# ESP32-H4 register map
Vendor: ESPRESSIF SYSTEMS (SHANGHAI) CO., LTD.; Series: ESP32 H-Series; File version: 1
CPU: RV32IMAC r0p0, little endian, no MPU, no FPU, 0 interrupt priority bits
Address unit: 32 bits
Registers are 32-bit, read-write, reset 0x0 unless marked. A register's access mark holds for its fields unless they carry their own. Offsets are from the block's base; [hi:lo] are bit positions; {n}, {i} and the like mark numbered series.

## INTERRUPT_CORE0 — Interrupt Controller (Core 0)
Base 0x6009A000
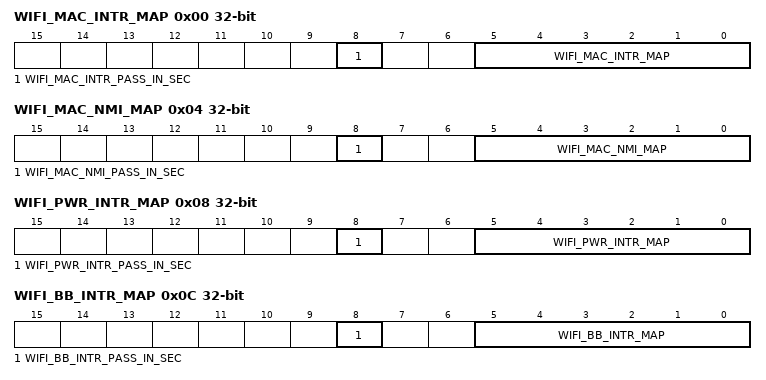
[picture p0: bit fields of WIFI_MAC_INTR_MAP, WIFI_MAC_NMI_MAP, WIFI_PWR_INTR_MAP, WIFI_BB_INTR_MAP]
0x00 WIFI_MAC_INTR_MAP — WIFI_MAC_INTR mapping register
  [8] WIFI_MAC_INTR_PASS_IN_SEC — Configures the PASS_IN_SEC flag of the interrupt source.
  [5:0] WIFI_MAC_INTR_MAP — Configures the interrupt source into one CPU interrupt.
0x04 WIFI_MAC_NMI_MAP — WIFI_MAC_NMI mapping register
  [8] WIFI_MAC_NMI_PASS_IN_SEC — Configures the PASS_IN_SEC flag of the interrupt source.
  [5:0] WIFI_MAC_NMI_MAP — Configures the interrupt source into one CPU interrupt.
0x08 WIFI_PWR_INTR_MAP — WIFI_PWR_INTR mapping register
  [8] WIFI_PWR_INTR_PASS_IN_SEC — Configures the PASS_IN_SEC flag of the interrupt source.
  [5:0] WIFI_PWR_INTR_MAP — Configures the interrupt source into one CPU interrupt.
0x0C WIFI_BB_INTR_MAP — WIFI_BB_INTR mapping register
  [8] WIFI_BB_INTR_PASS_IN_SEC — Configures the PASS_IN_SEC flag of the interrupt source.
  [5:0] WIFI_BB_INTR_MAP — Configures the interrupt source into one CPU interrupt.
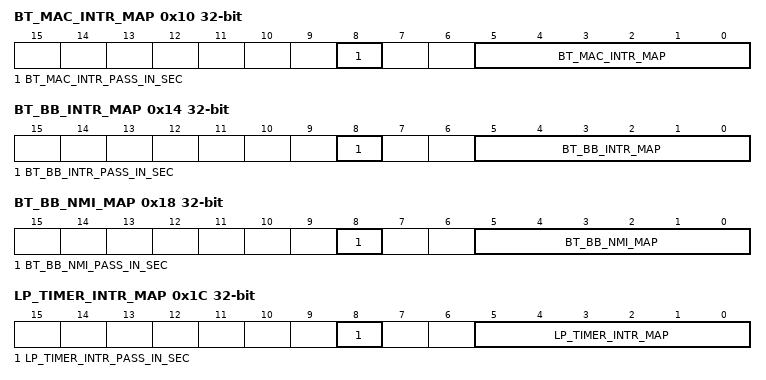
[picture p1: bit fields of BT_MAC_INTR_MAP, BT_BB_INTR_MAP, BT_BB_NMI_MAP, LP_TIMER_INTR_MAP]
0x10 BT_MAC_INTR_MAP — BT_MAC_INTR mapping register
  [8] BT_MAC_INTR_PASS_IN_SEC — Configures the PASS_IN_SEC flag of the interrupt source.
  [5:0] BT_MAC_INTR_MAP — Configures the interrupt source into one CPU interrupt.
0x14 BT_BB_INTR_MAP — BT_BB_INTR mapping register
  [8] BT_BB_INTR_PASS_IN_SEC — Configures the PASS_IN_SEC flag of the interrupt source.
  [5:0] BT_BB_INTR_MAP — Configures the interrupt source into one CPU interrupt.
0x18 BT_BB_NMI_MAP — BT_BB_NMI mapping register
  [8] BT_BB_NMI_PASS_IN_SEC — Configures the PASS_IN_SEC flag of the interrupt source.
  [5:0] BT_BB_NMI_MAP — Configures the interrupt source into one CPU interrupt.
0x1C LP_TIMER_INTR_MAP — LP_TIMER_INTR mapping register
  [8] LP_TIMER_INTR_PASS_IN_SEC — Configures the PASS_IN_SEC flag of the interrupt source.
  [5:0] LP_TIMER_INTR_MAP — Configures the interrupt source into one CPU interrupt.
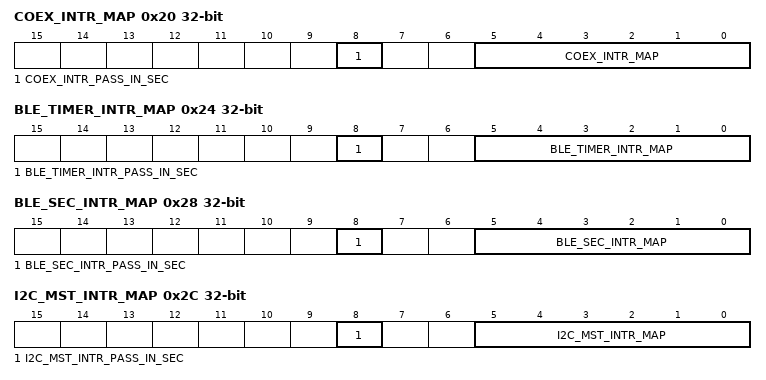
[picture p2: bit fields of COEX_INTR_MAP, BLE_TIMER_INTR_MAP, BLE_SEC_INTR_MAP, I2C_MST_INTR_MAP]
0x20 COEX_INTR_MAP — COEX_INTR mapping register
  [8] COEX_INTR_PASS_IN_SEC — Configures the PASS_IN_SEC flag of the interrupt source.
  [5:0] COEX_INTR_MAP — Configures the interrupt source into one CPU interrupt.
0x24 BLE_TIMER_INTR_MAP — BLE_TIMER_INTR mapping register
  [8] BLE_TIMER_INTR_PASS_IN_SEC — Configures the PASS_IN_SEC flag of the interrupt source.
  [5:0] BLE_TIMER_INTR_MAP — Configures the interrupt source into one CPU interrupt.
0x28 BLE_SEC_INTR_MAP — BLE_SEC_INTR mapping register
  [8] BLE_SEC_INTR_PASS_IN_SEC — Configures the PASS_IN_SEC flag of the interrupt source.
  [5:0] BLE_SEC_INTR_MAP — Configures the interrupt source into one CPU interrupt.
0x2C I2C_MST_INTR_MAP — I2C_MST_INTR mapping register
  [8] I2C_MST_INTR_PASS_IN_SEC — Configures the PASS_IN_SEC flag of the interrupt source.
  [5:0] I2C_MST_INTR_MAP — Configures the interrupt source into one CPU interrupt.
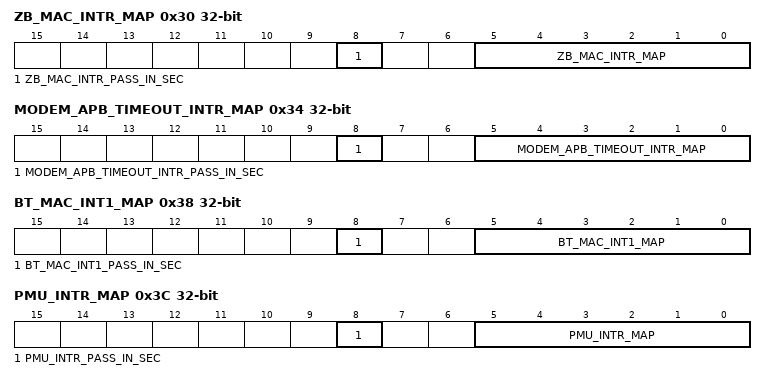
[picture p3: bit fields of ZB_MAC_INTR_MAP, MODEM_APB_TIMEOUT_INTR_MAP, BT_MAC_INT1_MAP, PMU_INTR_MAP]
0x30 ZB_MAC_INTR_MAP — ZB_MAC_INTR mapping register
  [8] ZB_MAC_INTR_PASS_IN_SEC — Configures the PASS_IN_SEC flag of the interrupt source.
  [5:0] ZB_MAC_INTR_MAP — Configures the interrupt source into one CPU interrupt.
0x34 MODEM_APB_TIMEOUT_INTR_MAP — MODEM_APB_TIMEOUT_INTR mapping register
  [8] MODEM_APB_TIMEOUT_INTR_PASS_IN_SEC — Configures the PASS_IN_SEC flag of the interrupt source.
  [5:0] MODEM_APB_TIMEOUT_INTR_MAP — Configures the interrupt source into one CPU interrupt.
0x38 BT_MAC_INT1_MAP — BT_MAC_INT1 mapping register
  [8] BT_MAC_INT1_PASS_IN_SEC — Configures the PASS_IN_SEC flag of the interrupt source.
  [5:0] BT_MAC_INT1_MAP — Configures the interrupt source into one CPU interrupt.
0x3C PMU_INTR_MAP — PMU_INTR mapping register
  [8] PMU_INTR_PASS_IN_SEC — Configures the PASS_IN_SEC flag of the interrupt source.
  [5:0] PMU_INTR_MAP — Configures the interrupt source into one CPU interrupt.
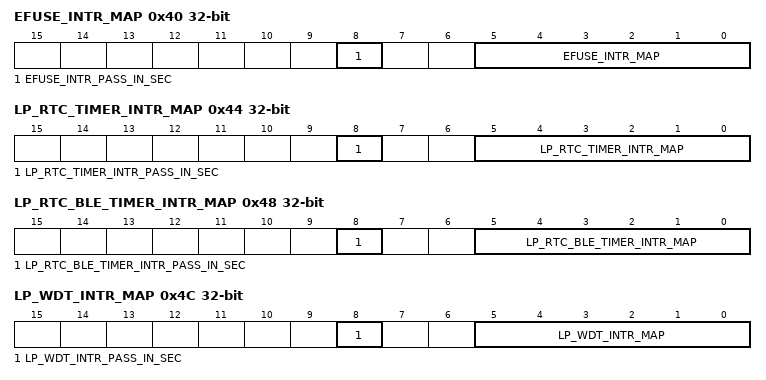
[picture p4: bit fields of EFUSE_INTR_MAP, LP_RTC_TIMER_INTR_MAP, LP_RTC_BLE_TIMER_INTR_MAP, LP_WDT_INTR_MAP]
0x40 EFUSE_INTR_MAP — EFUSE_INTR mapping register
  [8] EFUSE_INTR_PASS_IN_SEC — Configures the PASS_IN_SEC flag of the interrupt source.
  [5:0] EFUSE_INTR_MAP — Configures the interrupt source into one CPU interrupt.
0x44 LP_RTC_TIMER_INTR_MAP — LP_RTC_TIMER_INTR mapping register
  [8] LP_RTC_TIMER_INTR_PASS_IN_SEC — Configures the PASS_IN_SEC flag of the interrupt source.
  [5:0] LP_RTC_TIMER_INTR_MAP — Configures the interrupt source into one CPU interrupt.
0x48 LP_RTC_BLE_TIMER_INTR_MAP — LP_RTC_BLE_TIMER_INTR mapping register
  [8] LP_RTC_BLE_TIMER_INTR_PASS_IN_SEC — Configures the PASS_IN_SEC flag of the interrupt source.
  [5:0] LP_RTC_BLE_TIMER_INTR_MAP — Configures the interrupt source into one CPU interrupt.
0x4C LP_WDT_INTR_MAP — LP_WDT_INTR mapping register
  [8] LP_WDT_INTR_PASS_IN_SEC — Configures the PASS_IN_SEC flag of the interrupt source.
  [5:0] LP_WDT_INTR_MAP — Configures the interrupt source into one CPU interrupt.
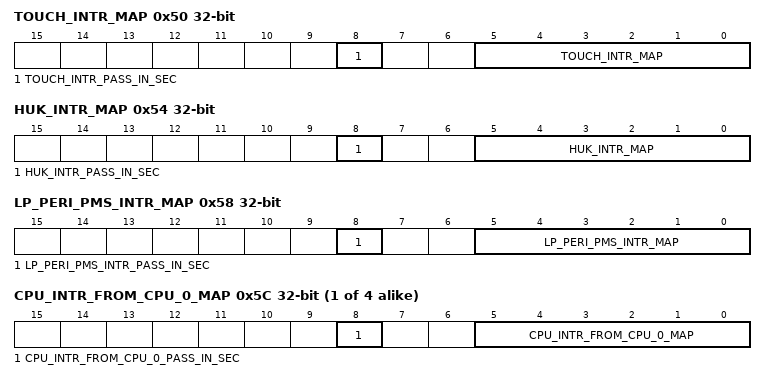
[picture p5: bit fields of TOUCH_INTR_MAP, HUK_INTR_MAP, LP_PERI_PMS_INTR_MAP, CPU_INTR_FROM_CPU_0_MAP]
0x50 TOUCH_INTR_MAP — TOUCH_INTR mapping register
  [8] TOUCH_INTR_PASS_IN_SEC — Configures the PASS_IN_SEC flag of the interrupt source.
  [5:0] TOUCH_INTR_MAP — Configures the interrupt source into one CPU interrupt.
0x54 HUK_INTR_MAP — HUK_INTR mapping register
  [8] HUK_INTR_PASS_IN_SEC — Configures the PASS_IN_SEC flag of the interrupt source.
  [5:0] HUK_INTR_MAP — Configures the interrupt source into one CPU interrupt.
0x58 LP_PERI_PMS_INTR_MAP — LP_PERI_PMS_INTR mapping register
  [8] LP_PERI_PMS_INTR_PASS_IN_SEC — Configures the PASS_IN_SEC flag of the interrupt source.
  [5:0] LP_PERI_PMS_INTR_MAP — Configures the interrupt source into one CPU interrupt.
{0x5C+4i} CPU_INTR_FROM_CPU_{i}_MAP (i=0..3) — CPU_INTR_FROM_CPU_{i} mapping register
  [8] CPU_INTR_FROM_CPU_{i}_PASS_IN_SEC — Configures the PASS_IN_SEC flag of the interrupt source.
  [5:0] CPU_INTR_FROM_CPU_{i}_MAP — Configures the interrupt source into one CPU interrupt.
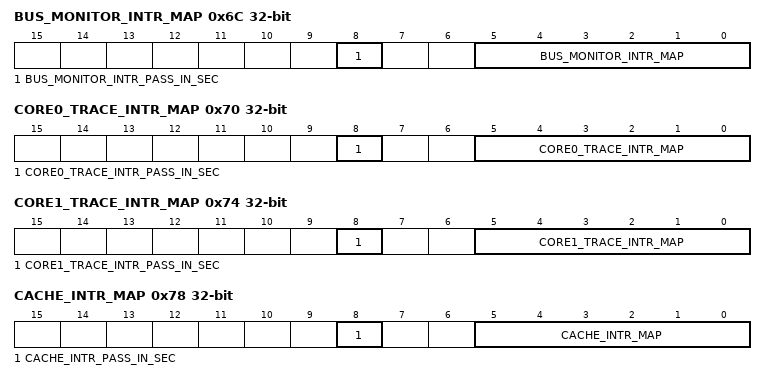
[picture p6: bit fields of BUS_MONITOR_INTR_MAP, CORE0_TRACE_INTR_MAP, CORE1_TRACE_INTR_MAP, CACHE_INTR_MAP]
0x6C BUS_MONITOR_INTR_MAP — BUS_MONITOR_INTR mapping register
  [8] BUS_MONITOR_INTR_PASS_IN_SEC — Configures the PASS_IN_SEC flag of the interrupt source.
  [5:0] BUS_MONITOR_INTR_MAP — Configures the interrupt source into one CPU interrupt.
0x70 CORE0_TRACE_INTR_MAP — CORE0_TRACE_INTR mapping register
  [8] CORE0_TRACE_INTR_PASS_IN_SEC — Configures the PASS_IN_SEC flag of the interrupt source.
  [5:0] CORE0_TRACE_INTR_MAP — Configures the interrupt source into one CPU interrupt.
0x74 CORE1_TRACE_INTR_MAP — CORE1_TRACE_INTR mapping register
  [8] CORE1_TRACE_INTR_PASS_IN_SEC — Configures the PASS_IN_SEC flag of the interrupt source.
  [5:0] CORE1_TRACE_INTR_MAP — Configures the interrupt source into one CPU interrupt.
0x78 CACHE_INTR_MAP — CACHE_INTR mapping register
  [8] CACHE_INTR_PASS_IN_SEC — Configures the PASS_IN_SEC flag of the interrupt source.
  [5:0] CACHE_INTR_MAP — Configures the interrupt source into one CPU interrupt.
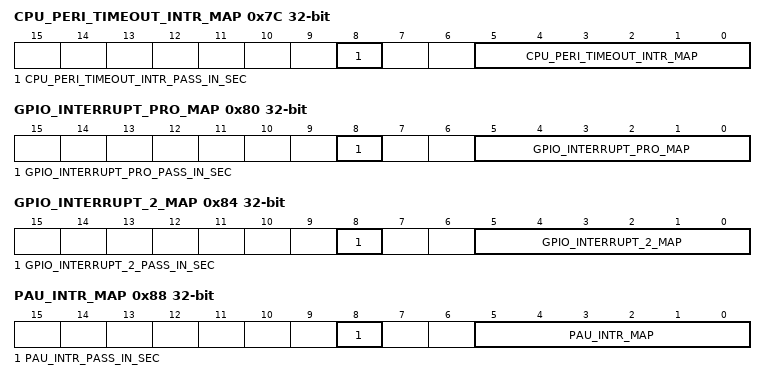
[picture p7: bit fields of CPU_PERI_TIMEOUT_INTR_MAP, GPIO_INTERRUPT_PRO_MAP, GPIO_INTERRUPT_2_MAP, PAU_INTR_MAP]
0x7C CPU_PERI_TIMEOUT_INTR_MAP — CPU_PERI_TIMEOUT_INTR mapping register
  [8] CPU_PERI_TIMEOUT_INTR_PASS_IN_SEC — Configures the PASS_IN_SEC flag of the interrupt source.
  [5:0] CPU_PERI_TIMEOUT_INTR_MAP — Configures the interrupt source into one CPU interrupt.
0x80 GPIO_INTERRUPT_PRO_MAP — GPIO_INTERRUPT_PRO mapping register
  [8] GPIO_INTERRUPT_PRO_PASS_IN_SEC — Configures the PASS_IN_SEC flag of the interrupt source.
  [5:0] GPIO_INTERRUPT_PRO_MAP — Configures the interrupt source into one CPU interrupt.
0x84 GPIO_INTERRUPT_2_MAP — GPIO_INTERRUPT_2 mapping register
  [8] GPIO_INTERRUPT_2_PASS_IN_SEC — Configures the PASS_IN_SEC flag of the interrupt source.
  [5:0] GPIO_INTERRUPT_2_MAP — Configures the interrupt source into one CPU interrupt.
0x88 PAU_INTR_MAP — PAU_INTR mapping register
  [8] PAU_INTR_PASS_IN_SEC — Configures the PASS_IN_SEC flag of the interrupt source.
  [5:0] PAU_INTR_MAP — Configures the interrupt source into one CPU interrupt.
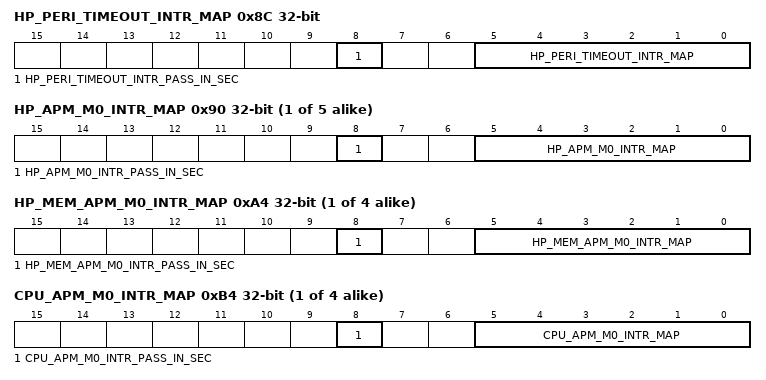
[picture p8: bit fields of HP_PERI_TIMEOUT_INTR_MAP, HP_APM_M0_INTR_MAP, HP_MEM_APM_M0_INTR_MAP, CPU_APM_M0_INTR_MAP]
0x8C HP_PERI_TIMEOUT_INTR_MAP — HP_PERI_TIMEOUT_INTR mapping register
  [8] HP_PERI_TIMEOUT_INTR_PASS_IN_SEC — Configures the PASS_IN_SEC flag of the interrupt source.
  [5:0] HP_PERI_TIMEOUT_INTR_MAP — Configures the interrupt source into one CPU interrupt.
{0x90+4i} HP_APM_M{i}_INTR_MAP (i=0..4) — HP_APM_M{i}_INTR mapping register
  [8] HP_APM_M{i}_INTR_PASS_IN_SEC — Configures the PASS_IN_SEC flag of the interrupt source.
  [5:0] HP_APM_M{i}_INTR_MAP — Configures the interrupt source into one CPU interrupt.
{0xA4+4i} HP_MEM_APM_M{i}_INTR_MAP (i=0..3) — HP_MEM_APM_M{i}_INTR mapping register
  [8] HP_MEM_APM_M{i}_INTR_PASS_IN_SEC — Configures the PASS_IN_SEC flag of the interrupt source.
  [5:0] HP_MEM_APM_M{i}_INTR_MAP — Configures the interrupt source into one CPU interrupt.
{0xB4+4i} CPU_APM_M{i}_INTR_MAP (i=0..3) — CPU_APM_M{i}_INTR mapping register
  [8] CPU_APM_M{i}_INTR_PASS_IN_SEC — Configures the PASS_IN_SEC flag of the interrupt source.
  [5:0] CPU_APM_M{i}_INTR_MAP — Configures the interrupt source into one CPU interrupt.
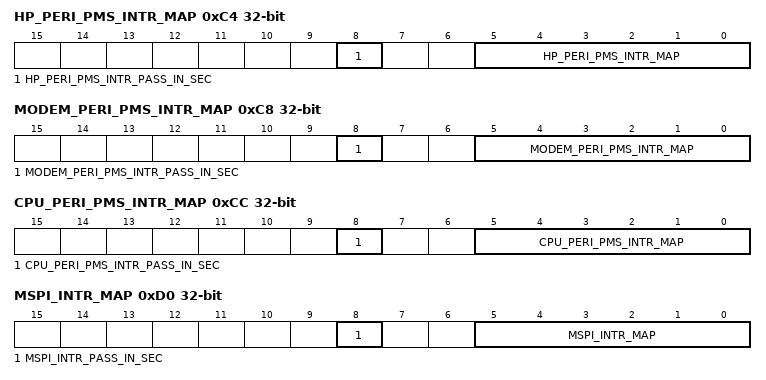
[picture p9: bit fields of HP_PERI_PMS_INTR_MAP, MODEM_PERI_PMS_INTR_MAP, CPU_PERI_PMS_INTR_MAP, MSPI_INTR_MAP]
0xC4 HP_PERI_PMS_INTR_MAP — HP_PERI_PMS_INTR mapping register
  [8] HP_PERI_PMS_INTR_PASS_IN_SEC — Configures the PASS_IN_SEC flag of the interrupt source.
  [5:0] HP_PERI_PMS_INTR_MAP — Configures the interrupt source into one CPU interrupt.
0xC8 MODEM_PERI_PMS_INTR_MAP — MODEM_PERI_PMS_INTR mapping register
  [8] MODEM_PERI_PMS_INTR_PASS_IN_SEC — Configures the PASS_IN_SEC flag of the interrupt source.
  [5:0] MODEM_PERI_PMS_INTR_MAP — Configures the interrupt source into one CPU interrupt.
0xCC CPU_PERI_PMS_INTR_MAP — CPU_PERI_PMS_INTR mapping register
  [8] CPU_PERI_PMS_INTR_PASS_IN_SEC — Configures the PASS_IN_SEC flag of the interrupt source.
  [5:0] CPU_PERI_PMS_INTR_MAP — Configures the interrupt source into one CPU interrupt.
0xD0 MSPI_INTR_MAP — MSPI_INTR mapping register
  [8] MSPI_INTR_PASS_IN_SEC — Configures the PASS_IN_SEC flag of the interrupt source.
  [5:0] MSPI_INTR_MAP — Configures the interrupt source into one CPU interrupt.
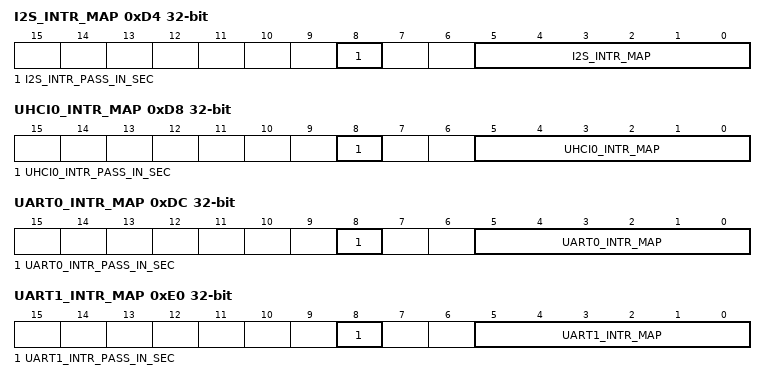
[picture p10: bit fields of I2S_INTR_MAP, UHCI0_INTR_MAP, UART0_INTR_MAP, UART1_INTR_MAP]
0xD4 I2S_INTR_MAP — I2S_INTR mapping register
  [8] I2S_INTR_PASS_IN_SEC — Configures the PASS_IN_SEC flag of the interrupt source.
  [5:0] I2S_INTR_MAP — Configures the interrupt source into one CPU interrupt.
0xD8 UHCI0_INTR_MAP — UHCI0_INTR mapping register
  [8] UHCI0_INTR_PASS_IN_SEC — Configures the PASS_IN_SEC flag of the interrupt source.
  [5:0] UHCI0_INTR_MAP — Configures the interrupt source into one CPU interrupt.
0xDC UART0_INTR_MAP — UART0_INTR mapping register
  [8] UART0_INTR_PASS_IN_SEC — Configures the PASS_IN_SEC flag of the interrupt source.
  [5:0] UART0_INTR_MAP — Configures the interrupt source into one CPU interrupt.
0xE0 UART1_INTR_MAP — UART1_INTR mapping register
  [8] UART1_INTR_PASS_IN_SEC — Configures the PASS_IN_SEC flag of the interrupt source.
  [5:0] UART1_INTR_MAP — Configures the interrupt source into one CPU interrupt.
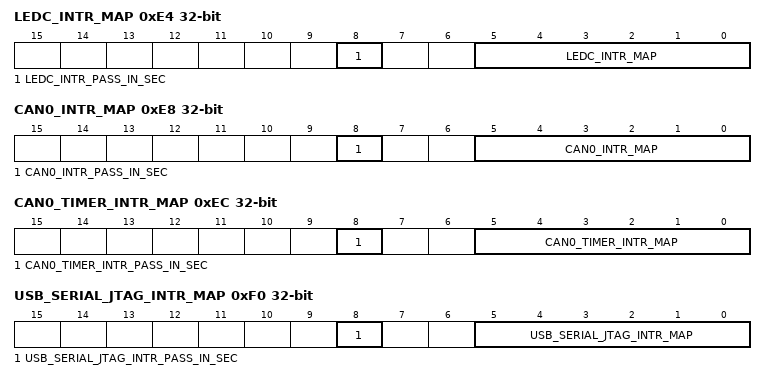
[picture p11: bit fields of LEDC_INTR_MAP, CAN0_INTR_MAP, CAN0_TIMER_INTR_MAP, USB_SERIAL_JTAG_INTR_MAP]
0xE4 LEDC_INTR_MAP — LEDC_INTR mapping register
  [8] LEDC_INTR_PASS_IN_SEC — Configures the PASS_IN_SEC flag of the interrupt source.
  [5:0] LEDC_INTR_MAP — Configures the interrupt source into one CPU interrupt.
0xE8 CAN0_INTR_MAP — CAN0_INTR mapping register
  [8] CAN0_INTR_PASS_IN_SEC — Configures the PASS_IN_SEC flag of the interrupt source.
  [5:0] CAN0_INTR_MAP — Configures the interrupt source into one CPU interrupt.
0xEC CAN0_TIMER_INTR_MAP — CAN0_TIMER_INTR mapping register
  [8] CAN0_TIMER_INTR_PASS_IN_SEC — Configures the PASS_IN_SEC flag of the interrupt source.
  [5:0] CAN0_TIMER_INTR_MAP — Configures the interrupt source into one CPU interrupt.
0xF0 USB_SERIAL_JTAG_INTR_MAP — USB_SERIAL_JTAG_INTR mapping register
  [8] USB_SERIAL_JTAG_INTR_PASS_IN_SEC — Configures the PASS_IN_SEC flag of the interrupt source.
  [5:0] USB_SERIAL_JTAG_INTR_MAP — Configures the interrupt source into one CPU interrupt.
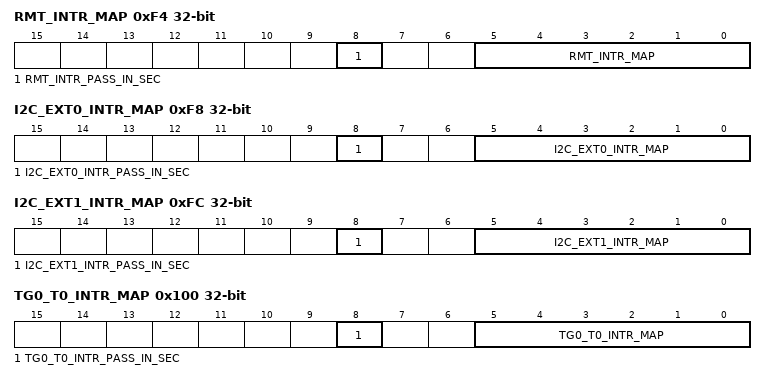
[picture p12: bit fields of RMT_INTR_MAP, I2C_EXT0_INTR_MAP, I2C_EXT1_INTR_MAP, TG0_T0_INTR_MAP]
0xF4 RMT_INTR_MAP — RMT_INTR mapping register
  [8] RMT_INTR_PASS_IN_SEC — Configures the PASS_IN_SEC flag of the interrupt source.
  [5:0] RMT_INTR_MAP — Configures the interrupt source into one CPU interrupt.
0xF8 I2C_EXT0_INTR_MAP — I2C_EXT0_INTR mapping register
  [8] I2C_EXT0_INTR_PASS_IN_SEC — Configures the PASS_IN_SEC flag of the interrupt source.
  [5:0] I2C_EXT0_INTR_MAP — Configures the interrupt source into one CPU interrupt.
0xFC I2C_EXT1_INTR_MAP — I2C_EXT1_INTR mapping register
  [8] I2C_EXT1_INTR_PASS_IN_SEC — Configures the PASS_IN_SEC flag of the interrupt source.
  [5:0] I2C_EXT1_INTR_MAP — Configures the interrupt source into one CPU interrupt.
0x100 TG0_T0_INTR_MAP — TG0_T0_INTR mapping register
  [8] TG0_T0_INTR_PASS_IN_SEC — Configures the PASS_IN_SEC flag of the interrupt source.
  [5:0] TG0_T0_INTR_MAP — Configures the interrupt source into one CPU interrupt.
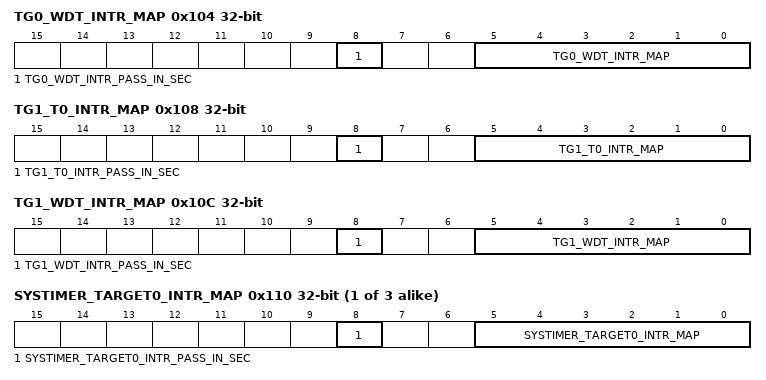
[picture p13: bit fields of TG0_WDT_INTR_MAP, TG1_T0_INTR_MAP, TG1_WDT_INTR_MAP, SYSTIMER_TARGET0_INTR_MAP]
0x104 TG0_WDT_INTR_MAP — TG0_WDT_INTR mapping register
  [8] TG0_WDT_INTR_PASS_IN_SEC — Configures the PASS_IN_SEC flag of the interrupt source.
  [5:0] TG0_WDT_INTR_MAP — Configures the interrupt source into one CPU interrupt.
0x108 TG1_T0_INTR_MAP — TG1_T0_INTR mapping register
  [8] TG1_T0_INTR_PASS_IN_SEC — Configures the PASS_IN_SEC flag of the interrupt source.
  [5:0] TG1_T0_INTR_MAP — Configures the interrupt source into one CPU interrupt.
0x10C TG1_WDT_INTR_MAP — TG1_WDT_INTR mapping register
  [8] TG1_WDT_INTR_PASS_IN_SEC — Configures the PASS_IN_SEC flag of the interrupt source.
  [5:0] TG1_WDT_INTR_MAP — Configures the interrupt source into one CPU interrupt.
{0x110+4i} SYSTIMER_TARGET{i}_INTR_MAP (i=0..2) — SYSTIMER_TARGET{i}_INTR mapping register
  [8] SYSTIMER_TARGET{i}_INTR_PASS_IN_SEC — Configures the PASS_IN_SEC flag of the interrupt source.
  [5:0] SYSTIMER_TARGET{i}_INTR_MAP — Configures the interrupt source into one CPU interrupt.
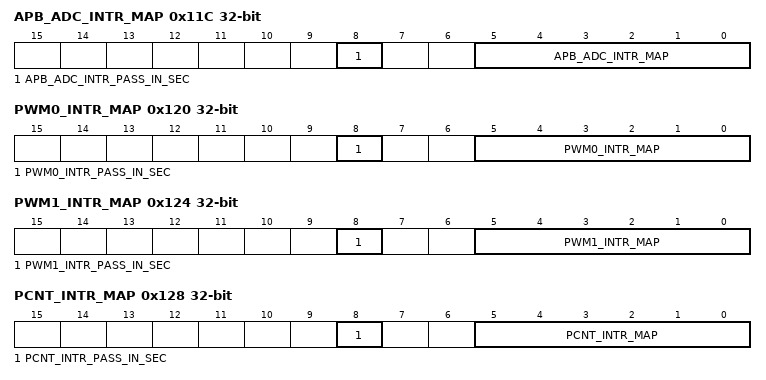
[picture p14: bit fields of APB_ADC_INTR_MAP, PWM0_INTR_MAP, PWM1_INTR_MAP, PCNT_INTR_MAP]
0x11C APB_ADC_INTR_MAP — APB_ADC_INTR mapping register
  [8] APB_ADC_INTR_PASS_IN_SEC — Configures the PASS_IN_SEC flag of the interrupt source.
  [5:0] APB_ADC_INTR_MAP — Configures the interrupt source into one CPU interrupt.
0x120 PWM0_INTR_MAP — PWM0_INTR mapping register
  [8] PWM0_INTR_PASS_IN_SEC — Configures the PASS_IN_SEC flag of the interrupt source.
  [5:0] PWM0_INTR_MAP — Configures the interrupt source into one CPU interrupt.
0x124 PWM1_INTR_MAP — PWM1_INTR mapping register
  [8] PWM1_INTR_PASS_IN_SEC — Configures the PASS_IN_SEC flag of the interrupt source.
  [5:0] PWM1_INTR_MAP — Configures the interrupt source into one CPU interrupt.
0x128 PCNT_INTR_MAP — PCNT_INTR mapping register
  [8] PCNT_INTR_PASS_IN_SEC — Configures the PASS_IN_SEC flag of the interrupt source.
  [5:0] PCNT_INTR_MAP — Configures the interrupt source into one CPU interrupt.
0x12C PARL_IO_TX_INTR_MAP — PARL_IO_TX_INTR mapping register
  [8] PARL_IO_TX_INTR_PASS_IN_SEC — Configures the PASS_IN_SEC flag of the interrupt source.
  [5:0] PARL_IO_TX_INTR_MAP — Configures the interrupt source into one CPU interrupt.
0x130 PARL_IO_RX_INTR_MAP — PARL_IO_RX_INTR mapping register
  [8] PARL_IO_RX_INTR_PASS_IN_SEC — Configures the PASS_IN_SEC flag of the interrupt source.
  [5:0] PARL_IO_RX_INTR_MAP — Configures the interrupt source into one CPU interrupt.
0x134 USB_OTG11_INTR_MAP — USB_OTG11_INTR mapping register
  [8] USB_OTG11_INTR_PASS_IN_SEC — Configures the PASS_IN_SEC flag of the interrupt source.
  [5:0] USB_OTG11_INTR_MAP — Configures the interrupt source into one CPU interrupt.
0x138 ASRC_CHNL0_INTR_MAP — ASRC_CHNL0_INTR mapping register
  [8] ASRC_CHNL0_INTR_PASS_IN_SEC — Configures the PASS_IN_SEC flag of the interrupt source.
  [5:0] ASRC_CHNL0_INTR_MAP — Configures the interrupt source into one CPU interrupt.
0x13C ASRC_CHNL1_INTR_MAP — ASRC_CHNL1_INTR mapping register
  [8] ASRC_CHNL1_INTR_PASS_IN_SEC — Configures the PASS_IN_SEC flag of the interrupt source.
  [5:0] ASRC_CHNL1_INTR_MAP — Configures the interrupt source into one CPU interrupt.
0x140 ZERO_DET_INTR_MAP — ZERO_DET_INTR mapping register
  [8] ZERO_DET_INTR_PASS_IN_SEC — Configures the PASS_IN_SEC flag of the interrupt source.
  [5:0] ZERO_DET_INTR_MAP — Configures the interrupt source into one CPU interrupt.
{0x144+4i} DMA_IN_CH{i}_INTR_MAP (i=0..4) — DMA_IN_CH{i}_INTR mapping register
  [8] DMA_IN_CH{i}_INTR_PASS_IN_SEC — Configures the PASS_IN_SEC flag of the interrupt source.
  [5:0] DMA_IN_CH{i}_INTR_MAP — Configures the interrupt source into one CPU interrupt.
{0x158+4i} DMA_OUT_CH{i}_INTR_MAP (i=0..4) — DMA_OUT_CH{i}_INTR mapping register
  [8] DMA_OUT_CH{i}_INTR_PASS_IN_SEC — Configures the PASS_IN_SEC flag of the interrupt source.
  [5:0] DMA_OUT_CH{i}_INTR_MAP — Configures the interrupt source into one CPU interrupt.
0x16C GPSPI2_INTR_MAP — GPSPI2_INTR mapping register
  [8] GPSPI2_INTR_PASS_IN_SEC — Configures the PASS_IN_SEC flag of the interrupt source.
  [5:0] GPSPI2_INTR_MAP — Configures the interrupt source into one CPU interrupt.
0x170 GPSPI3_INTR_MAP — GPSPI3_INTR mapping register
  [8] GPSPI3_INTR_PASS_IN_SEC — Configures the PASS_IN_SEC flag of the interrupt source.
  [5:0] GPSPI3_INTR_MAP — Configures the interrupt source into one CPU interrupt.
0x174 AES_INTR_MAP — AES_INTR mapping register
  [8] AES_INTR_PASS_IN_SEC — Configures the PASS_IN_SEC flag of the interrupt source.
  [5:0] AES_INTR_MAP — Configures the interrupt source into one CPU interrupt.
0x178 SHA_INTR_MAP — SHA_INTR mapping register
  [8] SHA_INTR_PASS_IN_SEC — Configures the PASS_IN_SEC flag of the interrupt source.
  [5:0] SHA_INTR_MAP — Configures the interrupt source into one CPU interrupt.
0x17C ECC_INTR_MAP — ECC_INTR mapping register
  [8] ECC_INTR_PASS_IN_SEC — Configures the PASS_IN_SEC flag of the interrupt source.
  [5:0] ECC_INTR_MAP — Configures the interrupt source into one CPU interrupt.
0x180 ECDSA_INTR_MAP — ECDSA_INTR mapping register
  [8] ECDSA_INTR_PASS_IN_SEC — Configures the PASS_IN_SEC flag of the interrupt source.
  [5:0] ECDSA_INTR_MAP — Configures the interrupt source into one CPU interrupt.
0x184 KM_INTR_MAP — KM_INTR mapping register
  [8] KM_INTR_PASS_IN_SEC — Configures the PASS_IN_SEC flag of the interrupt source.
  [5:0] KM_INTR_MAP — Configures the interrupt source into one CPU interrupt.
{0x188+4i} INT_STATUS_REG_{i} ro (i=0..2) — Status register for interrupt sources {32i} ~ {32i+31}
  [31:0] INT_STATUS_{i} — Represents the status of the interrupt sources within interrupt-index-range {32i} ~ {32i+31}. Each bit corresponds to one interrupt source 0:The corresponding interrupt source triggered an interrupt 1:No interrupt triggered
0x194 INT_STATUS_REG_3 ro — Status register for interrupt sources 96 ~ 97
  [1:0] INT_STATUS_3 — Represents the status of the interrupt sources within interrupt-index-range 96 ~ 97. Each bit corresponds to one interrupt source 0:The corresponding interrupt source triggered an interrupt 1:No interrupt triggered
{0x198+4i} SRC_PASS_IN_SEC_STATUS_{i} ro (i=0..2) — PASS_IN_SEC status register for interrupt sources {32i} ~ {32i+31}
  [31:0] INT_SRC_PASS_IN_SEC_STATUS_{i} — Represents the PASS_IN_SEC status of the interrupt sources within interrupt-index-range {32i} ~ {32i+31}. Each bit corresponds to one interrupt source 0:The corresponding interrupt source is not PASS_IN_SEC. 1:The corresponding interrupt source is PASS_IN_SEC.
0x1A4 SRC_PASS_IN_SEC_STATUS_3 ro — PASS_IN_SEC status register for interrupt sources 96 ~ 97
  [1:0] INT_SRC_PASS_IN_SEC_STATUS_3 — Represents the PASS_IN_SEC status of the interrupt sources with interrupt-index-range 96 ~ 97. Each bit corresponds to one interrupt source 0:The corresponding interrupt source is not PASS_IN_SEC. 1:The corresponding interrupt source is PASS_IN_SEC.
0x1A8 SIG_IDX_ASSERT_IN_SEC — reserved
  [5:0] INT_SIG_IDX_ASSERT_IN_SEC
0x1AC SECURE_STATUS ro — reserved
  [31:0] INT_SECURE_STATUS
0x1B0 CLOCK_GATE — Interrupt clock gating configure register
  [0] REG_CLK_EN
0x7FC INTERRUPT_DATE reset 0x2504040 — Version control register
  [27:0] INTERRUPT_DATE
